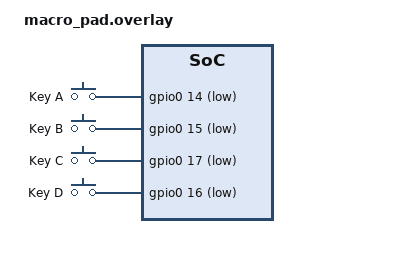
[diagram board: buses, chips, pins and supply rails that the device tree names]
/ {
    gpio_keys {
        compatible = "gpio-keys";
        label = "Direct Wired Keys";

        key_a: key_a {
            gpios = <&gpio0 14 (GPIO_PULL_UP | GPIO_ACTIVE_LOW)>;
            label = "Key A";
            linux,code = <KEY_A>;
        };

        key_b: key_b {
            gpios = <&gpio0 15 (GPIO_PULL_UP | GPIO_ACTIVE_LOW)>;
            label = "Key B";
            linux,code = <KEY_B>;
        };

        key_c: key_c {
            gpios = <&gpio0 17 (GPIO_PULL_UP | GPIO_ACTIVE_LOW)>;
            label = "Key C";
            linux,code = <KEY_C>;
        };

        key_d: key_d {
            gpios = <&gpio0 16 (GPIO_PULL_UP | GPIO_ACTIVE_LOW)>;
            label = "Key D";
            linux,code = <KEY_D>;
        };
    };
};
